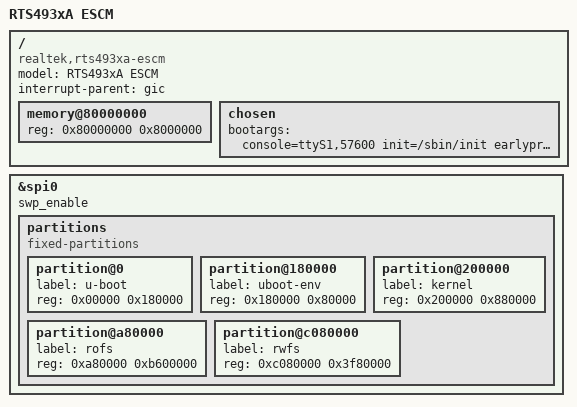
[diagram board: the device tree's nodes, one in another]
// SPDX-License-Identifier: GPL-2.0-or-later
// Copyright (c) 2025 Realtek Semiconductor Corp. All rights reserved.

#include "rts4930a.dtsi"

/ {
	model = "RTS493xA ESCM";
	compatible = "realtek,rts493xa-escm","realtek,rts493xa";

	#address-cells = <1>;
	#size-cells = <1>;
	interrupt-parent = <&gic>;

	memory@80000000 {
		device_type = "memory";
		reg = <0x80000000 0x8000000>;
	};

	chosen {
		bootargs = "console=ttyS1,57600 init=/sbin/init earlyprintk psci=enable root=/dev/mtdblock4 rootfstype=squashfs user_debug=31";
	};
};

&spi0 {
	status = "okay";
	swp_enable;
	partitions {
		compatible = "fixed-partitions";
		#address-cells = <1>;
		#size-cells = <1>;

		partition@0 {
			label = "u-boot";
			reg = <0x00000 0x180000>; //24*64K for uboot
		};

		partition@180000 {
			label = "uboot-env";
			reg = <0x180000 0x80000>; //8*64K for uboot env
		};

		partition@200000 {
			label = "kernel";
			reg = <0x200000 0x880000>; // 68*128K
		};

		partition@a80000 {
			label = "rofs";
			reg = <0xa80000 0xb600000>; //1456*128K
		};

		partition@c080000 {
			label = "rwfs";
			reg = <0xc080000 0x3f80000>; //508*128K
		};
	};
};
